# CC1350F128 register map
File version: 1.0
CPU: CM3 1.0, other endian, MPU, FPU, 3 interrupt priority bits
Registers are 32-bit, read-write, reset 0x0 unless marked. A register's access mark holds for its fields unless they carry their own. Offsets are from the block's base; [hi:lo] are bit positions; 'fields as' and 'values as' point back to an identical list.

## AON_BATMON — Always On (AON) Battery And Temperature MONitor (BATMON) residing in the AON domain Note: This module only supports 32 bit Read/Write access from MCU.
Base 0x40095000
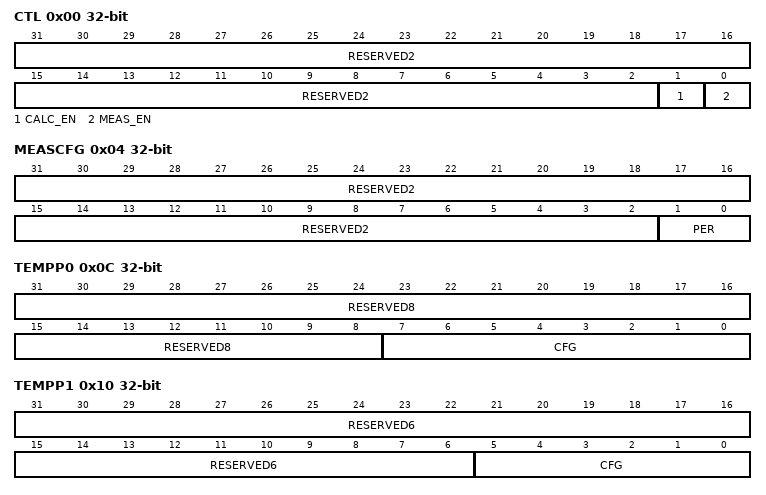
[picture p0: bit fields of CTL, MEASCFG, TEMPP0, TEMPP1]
0x00 CTL — Internal. Only to be used through TI provided API.
  [31:2] RESERVED2 ro — [31:2] Internal. Only to be used through TI provided API.
  [1] CALC_EN — [1:1] Internal. Only to be used through TI provided API.
  [0] MEAS_EN — [0:0] Internal. Only to be used through TI provided API.
0x04 MEASCFG — Internal. Only to be used through TI provided API.
  [31:2] RESERVED2 ro — [31:2] Internal. Only to be used through TI provided API.
  [1:0] PER — [1:0] Internal. Only to be used through TI provided API.
    3=32CYC (Internal. Only to be used through TI provided API.); 2=16CYC (Internal. Only to be used through TI provided API.); 1=8CYC (Internal. Only to be used through TI provided API.); 0=CONT (Internal. Only to be used through TI provided API.)
0x0C TEMPP0 — Internal. Only to be used through TI provided API.
  [31:8] RESERVED8 ro — [31:8] Internal. Only to be used through TI provided API.
  [7:0] CFG — [7:0] Internal. Only to be used through TI provided API.
0x10 TEMPP1 — Internal. Only to be used through TI provided API.
  [31:6] RESERVED6 ro — [31:6] Internal. Only to be used through TI provided API.
  [5:0] CFG — [5:0] Internal. Only to be used through TI provided API.
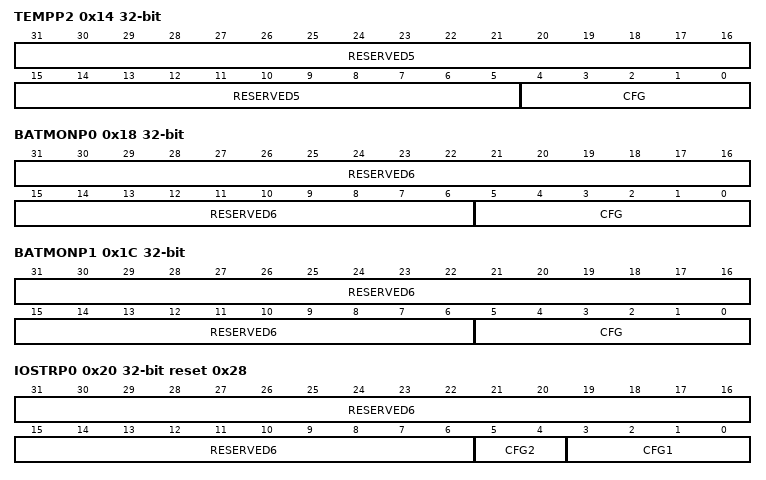
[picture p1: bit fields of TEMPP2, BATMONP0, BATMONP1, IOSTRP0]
0x14 TEMPP2 — Internal. Only to be used through TI provided API.
  [31:5] RESERVED5 ro — [31:5] Internal. Only to be used through TI provided API.
  [4:0] CFG — [4:0] Internal. Only to be used through TI provided API.
0x18 BATMONP0 — Internal. Only to be used through TI provided API.
  fields as TEMPP1
0x1C BATMONP1 — Internal. Only to be used through TI provided API.
  fields as TEMPP1
0x20 IOSTRP0 reset 0x28 — Internal. Only to be used through TI provided API.
  [31:6] RESERVED6 ro — [31:6] Internal. Only to be used through TI provided API.
  [5:4] CFG2 — [5:4] Internal. Only to be used through TI provided API.
  [3:0] CFG1 — [3:0] Internal. Only to be used through TI provided API.
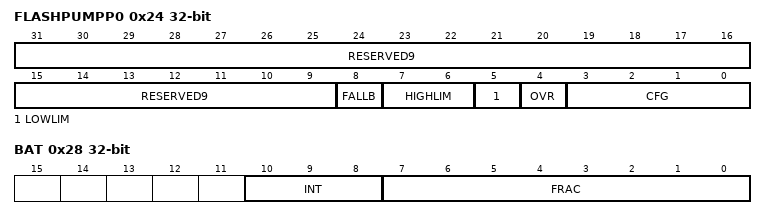
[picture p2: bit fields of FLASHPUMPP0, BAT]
0x24 FLASHPUMPP0 — Internal. Only to be used through TI provided API.
  [31:9] RESERVED9 ro — [31:9] Internal. Only to be used through TI provided API.
  [8] FALLB — [8:8] Internal. Only to be used through TI provided API.
  [7:6] HIGHLIM — [7:6] Internal. Only to be used through TI provided API.
  [5] LOWLIM — [5:5] Internal. Only to be used through TI provided API.
  [4] OVR — [4:4] Internal. Only to be used through TI provided API.
  [3:0] CFG — [3:0] Internal. Only to be used through TI provided API.
0x28 BAT — Last Measured Battery Voltage This register may be read while BATUPD.STAT = 1
  [10:8] INT ro — [10:8] Integer part: 0x0: 0V + fractional part ... 0x3: 3V + fractional part 0x4: 4V + fractional part
  [7:0] FRAC ro — [7:0] Fractional part, standard binary fractional encoding. 0x00: .0V ... 0x20: 1/8 = .125V 0x40: 1/4 = .25V 0x80: 1/2 = .5V ... 0xA0: 1/2 + 1/8 = .625V ... 0xFF: Max
0x2C BATUPD — Battery Update Indicates BAT Updates
  [0] STAT — [0:0] 0: No update since last clear 1: New battery voltage is present. Write 1 to clear the status.
0x30 TEMP — Temperature Last Measured Temperature in Degrees Celsius This register may be read while TEMPUPD.STAT = 1.
  [16:8] INT ro — [16:8] Integer part (signed) of temperature value. Total value = INTEGER + FRACTIONAL 2's complement encoding 0x100: Min value 0x1D8: -40C 0x1FF: -1C 0x00: 0C 0x1B: 27C 0x55: 85C 0xFF: Max value
0x34 TEMPUPD — Temperature Update Indicates TEMP Updates
  [0] STAT — [0:0] 0: No update since last clear 1: New temperature is present. Write 1 to clear the status.

## AON_IOC — Always On (AON) IO Controller - controls IO operation when the MCU IO Controller (IOC) is powered off and resides in the AON domain. Note: This module only supports 32 bit Read/Write access from MCU.
Base 0x40094000
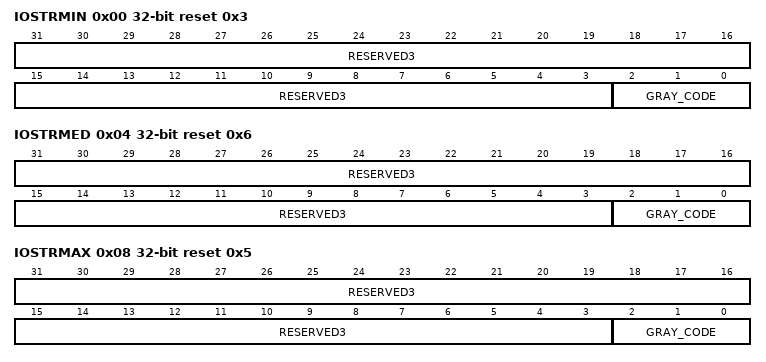
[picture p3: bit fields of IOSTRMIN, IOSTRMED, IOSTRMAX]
0x00 IOSTRMIN reset 0x3 — Internal. Only to be used through TI provided API.
  [31:3] RESERVED3 ro — [31:3] Internal. Only to be used through TI provided API.
  [2:0] GRAY_CODE — [2:0] Internal. Only to be used through TI provided API.
0x04 IOSTRMED reset 0x6 — Internal. Only to be used through TI provided API.
  fields as IOSTRMIN
0x08 IOSTRMAX reset 0x5 — Internal. Only to be used through TI provided API.
  fields as IOSTRMIN
0x0C IOCLATCH reset 0x1 — IO Latch Control Controls transparency of all latches holding I/O or configuration state from the MCU IOC
  [0] EN — [0:0] Controls latches between MCU IOC and AON_IOC. The latches are transparent by default. They must be closed prior to power off the domain(s) controlling the IOs in order to preserve IO values on external pins.
    1=TRANSP (Latches are transparent, meaning the value of the IO is directly controlled by the GPIO or peripheral value); 0=STATIC (Latches are static, meaning the current value on the IO pin is frozen by latches and kept even if GPIO module or a peripheral module is turned off)
0x10 CLK32KCTL reset 0x1 — SCLK_LF External Output Control
  [0] OE_N — [0:0] 0: Output enable active. SCLK_LF output on IO pin that has PORT_ID (e.g. IOC:IOCFG0.PORT_ID) set to AON_CLK32K. 1: Output enable not active
